# LPC11Axx register map
File version: 0.6
CPU: CM0 r0p0, little endian, no MPU, no FPU, 0x2 interrupt priority bits, 0x0 interrupts
Registers are 32-bit, read-write, reset 0x0 unless marked. A register's access mark holds for its fields unless they carry their own. Offsets are from the block's base; [hi:lo] are bit positions; 'fields as' and 'values as' point back to an identical list.

## IOCON — IOCON block
Base 0x40044000
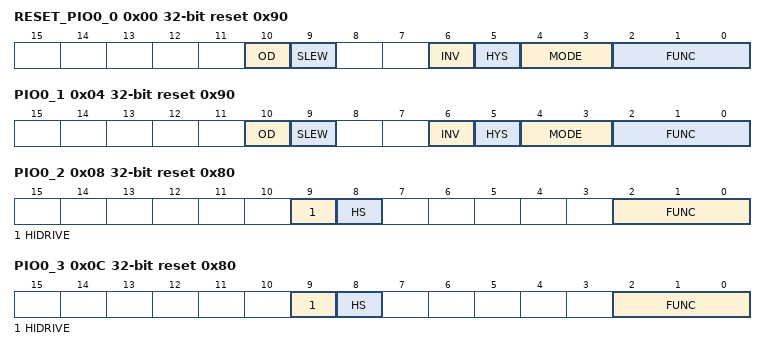
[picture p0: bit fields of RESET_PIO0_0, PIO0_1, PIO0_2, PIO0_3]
0x00 RESET_PIO0_0 reset 0x90 — I/O configuration register for pin RESET/PIO0_0
  [10] OD — Open-drain mode.
    0=DISABLE_; 1=OPEN_DRAIN_MODE_ENAB (Open-drain mode enabled. This is not a true open-drain mode. Input cannot be pulled up above VDD.)
  [9] SLEW — Driver slew rate
    0=SLOW (Slow. More outputs can be switched simultaneously.); 1=FAST
  [6] INV — Invert input
    0=INPUT_NOT_INVERTED_ (Input not inverted (HIGH on pin reads as 1, LOW on pin reads as 0).); 1=INPUT_INVERTED_HIGH (Input inverted (HIGH on pin reads as 0, LOW on pin reads as 1).)
  [5] HYS — Hysteresis.
    0=DISABLE_; 1=ENABLE_
  [4:3] MODE — Selects function mode (on-chip pull-up/pull-down resistor control).
    0=INACTIVE_NO_PULL_DO (Inactive (no pull-down/pull-up resistor enabled).); 1=PULL_DOWN_RESISTOR_E (Pull-down resistor enabled.); 2=PULL_UP_RESISTOR_ENA (Pull-up resistor enabled.); 3=REPEATER_MODE_
  [2:0] FUNC — Selects pin function for pin RESET/PIO0_0
    0=RESET (External reset input with fixed 20 ns glitch filter: A LOW on this pin resets the device, causing I/O ports and peripherals to take on their default states and processor execution to begin at address 0.); 1=PIO0_0 (General purpose digital input/output pin.)
0x04 PIO0_1 reset 0x90 — I/O configuration register for pin PIO0_1/RXD/CLKOUT/ CT32B0_MAT2/SSEL0/ CLKIN
  [10] OD — Open-drain mode.
    values as RESET_PIO0_0.OD
  [9] SLEW — Driver slew rate
    values as RESET_PIO0_0.SLEW
  [6] INV — Invert input
    values as RESET_PIO0_0.INV
  [5] HYS — Hysteresis.
    0=DISABLE_; 1=ENABLE_
  [4:3] MODE — Selects function mode (on-chip pull-up/pull-down resistor control).
    values as RESET_PIO0_0.MODE
  [2:0] FUNC — Selects pin function for pin PIO0_1/RXD/CLKOUT/ CT32B0_MAT2/SSEL0/ CLKIN
    0=PIO0_1 (General purpose digital input/output pin. A LOW level on this pin during reset starts the ISP command handler.); 1=RXD (Receiver data input for USART.); 2=CLKOUT (Clock output.); 3=CT32B0_MAT2 (Match output 2 for 32-bit timer 0.); 4=SSEL0 (Slave Select for SSP0.); 5=CLKIN (External clock input.)
0x08 PIO0_2 reset 0x80 — I/O configuration register for pin PIO0_2/SCL/ACMP_O/ TCK/SWCLK/ CT16B0_CAP0
  [9] HIDRIVE — Controls sink current.
    0=STANDARD (Standard; 4 mA sink current.); 1=HIGH (High; 20 mA sink current.)
  [8] HS — Controls glitch filter and slew rate.
    0=ENABLED; 1=DISABLED
  [2:0] FUNC — Selects pin function for pin PIO0_2/SCL/ACMP_O/ TCK/SWCLK/ CT16B0_CAP0
    0=PIO0_2 (General purpose digital input/output pin. High-current sink (20 mA) or standard-current sink (4 mA) programmable; true open-drain for all pin functions. Input glitch filter (50 ns) capable.); 1=SCL (I2C-bus clock (true open-drain) input/output. Input glitch filter (50 ns) capable.); 2=ACMP_O (Analog comparator output.); 3=TCK_SWCLK (Serial Wire Debug Clock (secondary for LQFP and HVQFN packages). Input glitch filter (50 ns) capable. For the WLCSP20 package only, this pin is configured to the SWCLK function by the boot loader after reset.); 4=CT16B0_CAP0 (Capture input 0 for 16-bit timer 0.Input glitch filter (50 ns) capable.)
0x0C PIO0_3 reset 0x80 — I/O configuration register for pin PIO0_3/SDA/ACMP_O/ SWDIO/CT16B1_CAP0
  [9] HIDRIVE — Controls sink current.
    values as PIO0_2.HIDRIVE
  [8] HS — Controls glitch filter and slew rate.
    0=ENABLED; 1=DISABLED
  [2:0] FUNC — Selects pin function for pin PIO0_3/SDA/ACMP_O/ SWDIO/CT16B1_CAP0
    0=PIO0_3 (General purpose digital input/output pin. High-current sink (20 mA) or standard-current sink (4 mA) programmable; true open-drain for all pin functions. Input glitch filter (50 ns) capable.); 1=SDA (I2C-bus data (true open-drain) input/output. Input glitch filter (50 ns) capable.); 2=ACMP_O (Analog comparator output.); 3=SWDIO (Serial Wire Debug I/O (secondary for LQFP and HVQFN packages). Input glitch filter (50 ns) capable. For the WLCSP20 package only, this pin is configured to the SWDIO function by the boot loader after reset.); 4=CT16B1_CAP0 (Capture input 0 for 16-bit timer 1. Input glitch filter (50 ns) capable.)
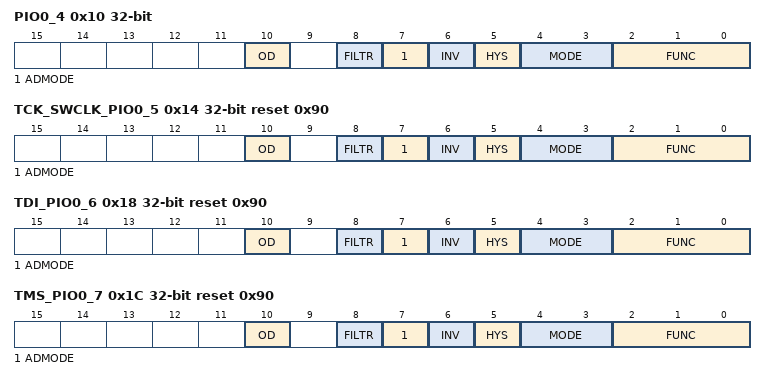
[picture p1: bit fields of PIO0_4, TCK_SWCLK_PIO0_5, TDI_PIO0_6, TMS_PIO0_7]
0x10 PIO0_4 reset not defined — I/O configuration register for pin PIO0_4/R/AOUT/ CT16B0_MAT1/MOSI0
  [10] OD — Open-drain mode.
    0=DISABLE_; 1=OPEN_DRAIN_MODE_ENAB (Open-drain mode enabled. This is not a true open-drain mode.)
  [8] FILTR — Selects 10 ns input glitch filter.
    0=FILTER_DISABLED_; 1=FILTER_ENABLED_
  [7] ADMODE — Selects Analog/Digital mode.
    0=ANALOG_INPUT_MODE_; 1=DIGITAL_FUNCTIONAL_M (Digital functional mode.)
  [6] INV — Invert input
    values as RESET_PIO0_0.INV
  [5] HYS — Hysteresis.
    0=DISABLE_; 1=ENABLE_
  [4:3] MODE — Selects function mode (on-chip pull-up/pull-down resistor control).
    values as RESET_PIO0_0.MODE
  [2:0] FUNC — Selects pin function for pin PIO0_4/R/AOUT/ CT16B0_MAT1/MOSI0
    0=PIO0_4 (General purpose digital input/output pin. Input glitch filter (10 ns) capable.); 1=R (Reserved.); 2=AOUT (D/A converter output.); 3=CT16B0_MAT1 (Match output 1 for 16-bit timer 0.); 4=MOSI0 (Master Out Slave In for SSP0. Input glitch filter (10 ns) capable.)
0x14 TCK_SWCLK_PIO0_5 reset 0x90 — I/O configuration register for pin TCK/SWCLK/PIO0_5/ R/CT16B0_MAT2/ SCK0
  [10] OD — Open-drain mode.
    values as PIO0_4.OD
  [8] FILTR — Selects 10 ns input glitch filter.
    0=FILTER_DISABLED_; 1=FILTER_ENABLED_
  [7] ADMODE — Selects Analog/Digital mode.
    values as PIO0_4.ADMODE
  [6] INV — Invert input
    values as RESET_PIO0_0.INV
  [5] HYS — Hysteresis.
    0=DISABLE_; 1=ENABLE_
  [4:3] MODE — Selects function mode (on-chip pull-up/pull-down resistor control).
    values as RESET_PIO0_0.MODE
  [2:0] FUNC — Selects pin function for pin TCK/SWCLK/PIO0_5/ R/CT16B0_MAT2/ SCK0
    0=TCK_SWCLK (Test clock TCK for JTAG interface and primary (default) Serial Wire Debug Clock. Input glitch filter (10 ns) capable.); 1=PIO0_5 (General purpose digital input/output pin. Input glitch filter (10 ns) capable.); 2=R (Reserved.); 3=CT16B0_MAT2 (Match output 2 for 16-bit timer 0.); 4=SCK0 (Serial clock for SSP0. Input glitch filter (10 ns) capable.)
0x18 TDI_PIO0_6 reset 0x90 — I/O configuration register for pin TDI/PIO0_6/AD0/ CT32B0_MAT3/MISO0
  [10] OD — Open-drain mode.
    values as PIO0_4.OD
  [8] FILTR — Selects 10 ns input glitch filter.
    0=FILTER_DISABLED_; 1=FILTER_ENABLED_
  [7] ADMODE — Selects Analog/Digital mode.
    values as PIO0_4.ADMODE
  [6] INV — Invert input
    values as RESET_PIO0_0.INV
  [5] HYS — Hysteresis.
    0=DISABLE_; 1=ENABLE_
  [4:3] MODE — Selects function mode (on-chip pull-up/pull-down resistor control).
    values as RESET_PIO0_0.MODE
  [2:0] FUNC — Selects pin function for pin TDI/PIO0_6/AD0/ CT32B0_MAT3/MISO0
    0=TDI (Test Data In for JTAG interface. Input glitch filter (10 ns) capable.); 1=PIO0_6 (General purpose digital input/output pin. Input glitch filter (10 ns) capable.); 2=AD0 (A/D converter input 0.); 3=CT32B0_MAT3 (Match output 3 for 32-bit timer 0.); 4=MISO0 (Master In Slave Out for SSP0. Input glitch filter (10 ns) capable.)
0x1C TMS_PIO0_7 reset 0x90 — I/O configuration register for pin TMS/PIO0_7/AD1/ CT32B1_CAP0/ CT16B0_MAT0
  [10] OD — Open-drain mode.
    values as PIO0_4.OD
  [8] FILTR — Selects 10 ns input glitch filter.
    0=FILTER_DISABLED_; 1=FILTER_ENABLED_
  [7] ADMODE — Selects Analog/Digital mode.
    values as PIO0_4.ADMODE
  [6] INV — Invert input
    values as RESET_PIO0_0.INV
  [5] HYS — Hysteresis.
    0=DISABLE_; 1=ENABLE_
  [4:3] MODE — Selects function mode (on-chip pull-up/pull-down resistor control).
    values as RESET_PIO0_0.MODE
  [2:0] FUNC — Selects pin function for pin TMS/PIO0_7/AD1/ CT32B1_CAP0/ CT16B0_MAT0
    0=TMS (Test Mode Select for JTAG interface. Input glitch filter (10 ns) capable.); 1=PIO0_7 (General purpose digital input/output pin. Input glitch filter (10 ns) capable.); 2=AD1 (A/D converter input 1.); 3=CT32B1_CAP0 (Capture input 0 for 32-bit timer 1. Input glitch filter (10 ns) capable.); 4=CT16B0_MAT0 (Match output 2 for 16-bit timer 0.)
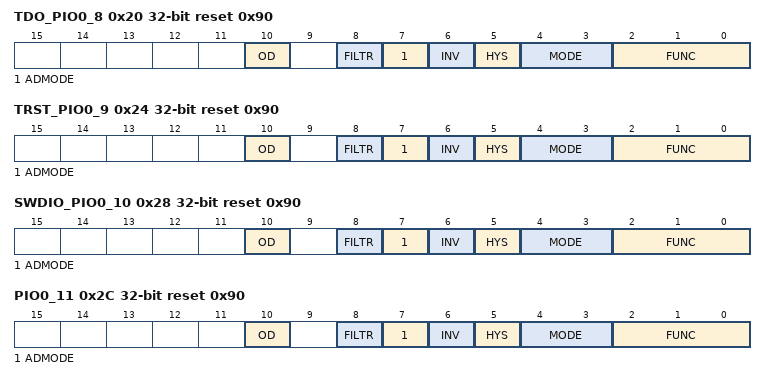
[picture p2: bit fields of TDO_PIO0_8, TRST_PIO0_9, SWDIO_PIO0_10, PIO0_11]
0x20 TDO_PIO0_8 reset 0x90 — I/O configuration register for pin TDO/PIO0_8/AD2/ CT32B1_MAT0/SCK1
  [10] OD — Open-drain mode.
    values as PIO0_4.OD
  [8] FILTR — Selects 10 ns input glitch filter.
    0=FILTER_DISABLED_; 1=FILTER_ENABLED_
  [7] ADMODE — Selects Analog/Digital mode.
    values as PIO0_4.ADMODE
  [6] INV — Invert input
    values as RESET_PIO0_0.INV
  [5] HYS — Hysteresis.
    0=DISABLE_; 1=ENABLE_
  [4:3] MODE — Selects function mode (on-chip pull-up/pull-down resistor control).
    values as RESET_PIO0_0.MODE
  [2:0] FUNC — Selects pin function for pin TDO/PIO0_8/AD2/ CT32B1_MAT0/SCK1
    0=TDO (Test Data Out for JTAG interface.); 1=PIO0_8 (General purpose digital input/output pin. Input glitch filter (10 ns) capable.); 2=AD2 (A/D converter input 2.); 3=CT32B1_MAT0 (Match output 0 for 32-bit timer 1.); 4=SCK1 (Serial clock for SSP1. Input glitch filter (10 ns) capable.)
0x24 TRST_PIO0_9 reset 0x90 — I/O configuration register for pin TRST/PIO0_9/AD3/CT32B1_MAT1/CT16B0_MAT1/CTS
  [10] OD — Open-drain mode.
    values as PIO0_4.OD
  [8] FILTR — Selects 10 ns input glitch filter.
    0=FILTER_DISABLED_; 1=FILTER_ENABLED_
  [7] ADMODE — Selects Analog/Digital mode.
    values as PIO0_4.ADMODE
  [6] INV — Invert input
    values as RESET_PIO0_0.INV
  [5] HYS — Hysteresis.
    0=DISABLE_; 1=ENABLE_
  [4:3] MODE — Selects function mode (on-chip pull-up/pull-down resistor control).
    values as RESET_PIO0_0.MODE
  [2:0] FUNC — Selects pin function for pin TRST/PIO0_9/AD3/CT32B1_MAT1/CT16B0_MAT1/CTS
    0=TRST (Test Reset for JTAG interface. Input glitch filter (10 ns) capable.); 1=PIO0_9 (General purpose digital input/output pin. Input glitch filter (10 ns) capable.); 2=AD3 (A/D converter, input 3.); 3=CT32B1_MAT1 (Match output 1 for 32-bit timer 1.); 4=CT16B0_MAT1 (Match output 1 for 16-bit timer 0.); 5=CTS (Clear To Send input for USART. Input glitch filter (10 ns) capable.)
0x28 SWDIO_PIO0_10 reset 0x90 — I/O configuration register for pin SWDIO/PIO0_10/AD4/ CT32B1_MAT2/ CT16B0_MAT2/RTS
  [10] OD — Open-drain mode.
    values as PIO0_4.OD
  [8] FILTR — Selects 10 ns input glitch filter.
    0=FILTER_DISABLED_; 1=FILTER_ENABLED_
  [7] ADMODE — Selects Analog/Digital mode.
    values as PIO0_4.ADMODE
  [6] INV — Invert input
    values as RESET_PIO0_0.INV
  [5] HYS — Hysteresis.
    0=DISABLE_; 1=ENABLE_
  [4:3] MODE — Selects function mode (on-chip pull-up/pull-down resistor control).
    values as RESET_PIO0_0.MODE
  [2:0] FUNC — Selects pin function for pin SWDIO/PIO0_10/AD4/ CT32B1_MAT2/ CT16B0_MAT2/RTS
    0=SWDIO (Primary (default) Serial Wire Debug I/O for the LQFP48 and HVQFN33 packages. For the WLCSP20 package, use PIO0_3. Input glitch filter (10 ns) capable.); 1=PIO0_10 (General purpose digital input/output pin. Input glitch filter (10 ns) capable.); 2=AD4 (A/D converter, input 4.); 3=CT32B1_MAT2 (Match output 2 for 32-bit timer 1.); 4=CT16B0_MAT2 (Match output 2 for 16-bit timer 0.); 5=RTS (Request To Send output for USART.)
0x2C PIO0_11 reset 0x90 — I/O configuration register for pin PIO0_11/SCLK/ AD5/CT32B1_MAT3/ CT32B0_CAP0
  [10] OD — Open-drain mode.
    values as PIO0_4.OD
  [8] FILTR — Selects 10 ns input glitch filter.
    0=FILTER_DISABLED_; 1=FILTER_ENABLED_
  [7] ADMODE — Selects Analog/Digital mode.
    values as PIO0_4.ADMODE
  [6] INV — Invert input
    values as RESET_PIO0_0.INV
  [5] HYS — Hysteresis.
    0=DISABLE_; 1=ENABLE_
  [4:3] MODE — Selects function mode (on-chip pull-up/pull-down resistor control).
    values as RESET_PIO0_0.MODE
  [2:0] FUNC — Selects pin function for pin PIO0_11/SCLK/ AD5/CT32B1_MAT3/ CT32B0_CAP0
    0=PIO0_11 (General purpose digital input/output pin. Input glitch filter (10 ns) capable.); 1=SCLK (Serial clock for USART. Input glitch filter (10 ns) capable.); 2=AD5 (A/D converter, input 5.); 3=CT32B1_MAT3 (Match output 3 for 32-bit timer 1.); 4=CT32B0_CAP0 (Capture input 0 for 32-bit timer 0. Input glitch filter (10 ns) capable.)
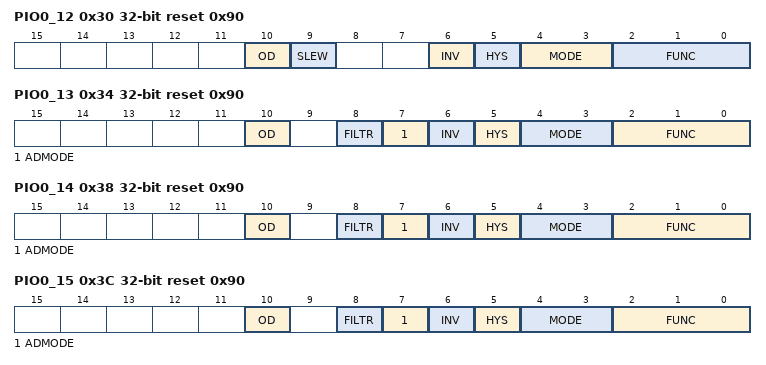
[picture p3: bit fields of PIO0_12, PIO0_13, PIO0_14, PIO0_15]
0x30 PIO0_12 reset 0x90 — I/O configuration register for pin PIO0_12/RXD/ ACMP_O/ CT32B0_MAT0/SCL/ CLKIN
  [10] OD — Open-drain mode.
    values as RESET_PIO0_0.OD
  [9] SLEW — Driver slew rate
    values as RESET_PIO0_0.SLEW
  [6] INV — Invert input
    values as RESET_PIO0_0.INV
  [5] HYS — Hysteresis.
    0=DISABLE_; 1=ENABLE_
  [4:3] MODE — Selects function mode (on-chip pull-up/pull-down resistor control).
    values as RESET_PIO0_0.MODE
  [2:0] FUNC — Selects pin function for pin PIO0_12/RXD/ ACMP_O/ CT32B0_MAT0/SCL/ CLKIN
    0=PIO0_12 (General purpose digital input/output pin.); 1=RXD (Receiver data input for USART. This pin is used for ISP communication.); 2=ACMP_O (Analog comparator output.); 3=CT32B0_MAT0 (Match output 0 for 32-bit timer 0.); 4=SCL (I2C-bus clock input/output. This is not an I2C-bus open-drain pin[8].); 5=CLKIN (External clock input.)
0x34 PIO0_13 reset 0x90 — I/O configuration register for pin PIO0_13/TXD/ ACMP_I2/ CT32B0_MAT1/SDA
  [10] OD — Open-drain mode.
    values as PIO0_4.OD
  [8] FILTR — Selects 10 ns input glitch filter.
    0=FILTER_DISABLED_; 1=FILTER_ENABLED_
  [7] ADMODE — Selects Analog/Digital mode.
    values as PIO0_4.ADMODE
  [6] INV — Invert input
    values as RESET_PIO0_0.INV
  [5] HYS — Hysteresis.
    0=DISABLE_; 1=ENABLE_
  [4:3] MODE — Selects function mode (on-chip pull-up/pull-down resistor control).
    values as RESET_PIO0_0.MODE
  [2:0] FUNC — Selects pin function for pin PIO0_13/TXD/ ACMP_I2/ CT32B0_MAT1/SDA
    0=PIO0_13 (General purpose digital input/output pin. Input glitch filter (10 ns) capable.); 1=TXD (Transmitter data output for USART. This pin is used for ISP communication.); 2=ACMP_I2 (Analog comparator input 2.); 3=CT32B0_MAT1 (Match output 1 for 32-bit timer 0.); 4=SDA (I2C-bus data input/output. This is not an I2C-bus open-drain pin[8]. Input glitch filter (10 ns) capable.)
0x38 PIO0_14 reset 0x90 — I/O configuration register for pin PIO0_14/MISO1/AD6/CT32B0_CAP1/CT16B1_MAT1/VDDCMP
  [10] OD — Open-drain mode.
    values as PIO0_4.OD
  [8] FILTR — Selects 10 ns input glitch filter.
    0=FILTER_DISABLED_; 1=FILTER_ENABLED_
  [7] ADMODE — Selects Analog/Digital mode.
    values as PIO0_4.ADMODE
  [6] INV — Invert input
    values as RESET_PIO0_0.INV
  [5] HYS — Hysteresis.
    0=DISABLE_; 1=ENABLE_
  [4:3] MODE — Selects function mode (on-chip pull-up/pull-down resistor control).
    values as RESET_PIO0_0.MODE
  [2:0] FUNC — Selects pin function for pin PIO0_14/MISO1/AD6/CT32B0_CAP1/CT16B1_MAT1/xxxCMP
    0=PIO0_14 (General purpose digital input/output pin. Input glitch filter (10 ns) capable.); 1=MISO1 (Master In Slave Out for SSP1. Input glitch filter (10 ns) capable.); 2=AD6 (A/D converter, input 6.); 3=CT32B0_CAP1 (Capture input 1 for 32-bit timer 0. Input glitch filter (10 ns) capable.); 4=CT16B1_MAT1 (Match output 1 for 16-bit timer 1.); 5=VDDCMP (Analog comparator alternate reference voltage.)
0x3C PIO0_15 reset 0x90 — I/O configuration register for pin PIO0_15/TXD/AD7/ CT32B0_CAP2/SDA
  [10] OD — Open-drain mode.
    values as PIO0_4.OD
  [8] FILTR — Selects 10 ns input glitch filter.
    0=FILTER_DISABLED_; 1=FILTER_ENABLED_
  [7] ADMODE — Selects Analog/Digital mode.
    values as PIO0_4.ADMODE
  [6] INV — Invert input
    values as RESET_PIO0_0.INV
  [5] HYS — Hysteresis.
    0=DISABLE_; 1=ENABLE_
  [4:3] MODE — Selects function mode (on-chip pull-up/pull-down resistor control).
    values as RESET_PIO0_0.MODE
  [2:0] FUNC — Selects pin function for pin PIO0_15/TXD/AD7/ CT32B0_CAP2/SDA
    0=PIO0_15 (General purpose digital input/output pin. Input glitch filter (10 ns) capable.); 1=TXD (Transmitter data output for USART.); 2=AD7 (A/D converter, input 7.); 3=CT32B0_CAP2 (Capture input 2 for 32-bit timer 0. Input glitch filter (10 ns) capable.); 4=SDA (I2C-bus data input/output. This is not an I2C-bus open-drain pin[8]. Input glitch filter (10 ns) capable.)
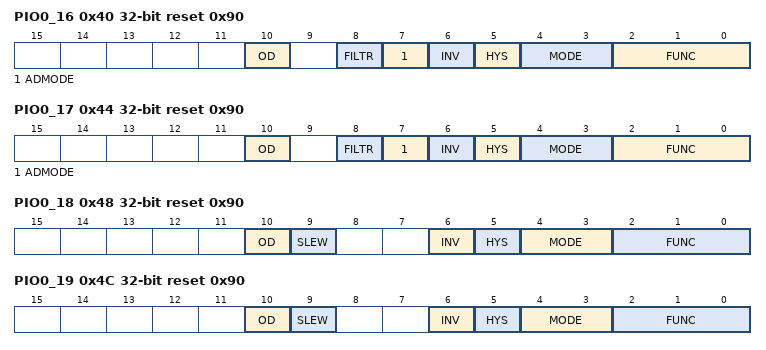
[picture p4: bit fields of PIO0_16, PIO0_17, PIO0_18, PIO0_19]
0x40 PIO0_16 reset 0x90 — I/O configuration register for pin PIO0_16/ ATRG0/ACMP_I3/ CT16B0_CAP1/SCL
  [10] OD — Open-drain mode.
    values as PIO0_4.OD
  [8] FILTR — Selects 10 ns input glitch filter.
    0=FILTER_DISABLED_; 1=FILTER_ENABLED_
  [7] ADMODE — Selects Analog/Digital mode.
    values as PIO0_4.ADMODE
  [6] INV — Invert input
    values as RESET_PIO0_0.INV
  [5] HYS — Hysteresis.
    0=DISABLE_; 1=ENABLE_
  [4:3] MODE — Selects function mode (on-chip pull-up/pull-down resistor control).
    values as RESET_PIO0_0.MODE
  [2:0] FUNC — Selects pin function for pin PIO0_16/ ATRG0/ACMP_I3/ CT16B0_CAP1/SCL
    0=PIO0_16 (General purpose digital input/output pin. Input glitch filter (10 ns) capable.); 1=ATRG0 (Conversion trigger 0 for ADC or DAC. Input glitch filter (10 ns) capable.); 2=ACMP_I3 (Analog comparator input 3.); 3=CT16B0_CAP1 (Capture input 1 for 16-bit timer 0. Input glitch filter (10 ns) capable.); 4=SCL (I2C-bus clock input/output. This is not an I2C-bus open-drain pin[8]. Input glitch filter (10 ns) capable.)
0x44 PIO0_17 reset 0x90 — I/O configuration register for pin PIO0_17/ ATRG1/ACMP_I4/ CT16B0_CAP2/ CT16B0_MAT0
  [10] OD — Open-drain mode.
    values as PIO0_4.OD
  [8] FILTR — Selects 10 ns input glitch filter.
    0=FILTER_DISABLED_; 1=FILTER_ENABLED_
  [7] ADMODE — Selects Analog/Digital mode.
    values as PIO0_4.ADMODE
  [6] INV — Invert input
    values as RESET_PIO0_0.INV
  [5] HYS — Hysteresis.
    0=DISABLE_; 1=ENABLE_
  [4:3] MODE — Selects function mode (on-chip pull-up/pull-down resistor control).
    values as RESET_PIO0_0.MODE
  [2:0] FUNC — Selects pin function for pin PIO0_17/ ATRG1/ACMP_I4/ CT16B0_CAP2/ CT16B0_MAT0
    0=PIO0_17 (General purpose digital input/output pin. Input glitch filter (10 ns) capable.); 1=ATRG1 (Conversion trigger 1 for ADC or DAC. Input glitch filter (10 ns) capable.); 2=ACMP_I4 (Analog comparator input 4.); 3=CT16B0_CAP2 (Capture input 2 for 16-bit timer 0. Input glitch filter (10 ns) capable.); 4=CT16B0_MAT0 (Match output 0 for 16-bit timer 0.)
0x48 PIO0_18 reset 0x90 — I/O configuration register for pin PIO0_18/R/SSEL0/ CT16B0_CAP0/ CT16B1_CAP1
  [10] OD — Open-drain mode.
    values as RESET_PIO0_0.OD
  [9] SLEW — Driver slew rate
    values as RESET_PIO0_0.SLEW
  [6] INV — Invert input
    values as RESET_PIO0_0.INV
  [5] HYS — Hysteresis.
    0=DISABLE_; 1=ENABLE_
  [4:3] MODE — Selects function mode (on-chip pull-up/pull-down resistor control).
    values as RESET_PIO0_0.MODE
  [2:0] FUNC — Selects pin function for pin PIO0_18/R/SSEL0/ CT16B0_CAP0/ CT16B1_CAP1
    0=PIO0_18 (General purpose digital input/output pin.); 1=R (Reserved.); 2=SSEL0 (Slave Select for SSP0.); 3=CT16B0_CAP0 (Capture input 0 for 16-bit timer 0.); 4=CT16B1_CAP1 (Capture input 1 for 16-bit timer 1.)
0x4C PIO0_19 reset 0x90 — I/O configuration register for pin PIO0_19/CLKIN/ CLKOUT/ MOSI0/CT16B1_MAT0
  [10] OD — Open-drain mode.
    values as RESET_PIO0_0.OD
  [9] SLEW — Driver slew rate
    values as RESET_PIO0_0.SLEW
  [6] INV — Invert input
    values as RESET_PIO0_0.INV
  [5] HYS — Hysteresis.
    0=DISABLE_; 1=ENABLE_
  [4:3] MODE — Selects function mode (on-chip pull-up/pull-down resistor control).
    values as RESET_PIO0_0.MODE
  [2:0] FUNC — Selects pin function for pin PIO0_19/CLKIN/ CLKOUT/ MOSI0/CT16B1_MAT0
    0=PIO0_19 (General purpose digital input/output pin.); 1=CLKIN (External clock input.); 2=CLKOUT (Clock output.); 3=MOSI0 (Master Out Slave In for SSP0.); 4=CT16B1_MAT0 (Match output 0 for 16-bit timer 1.)
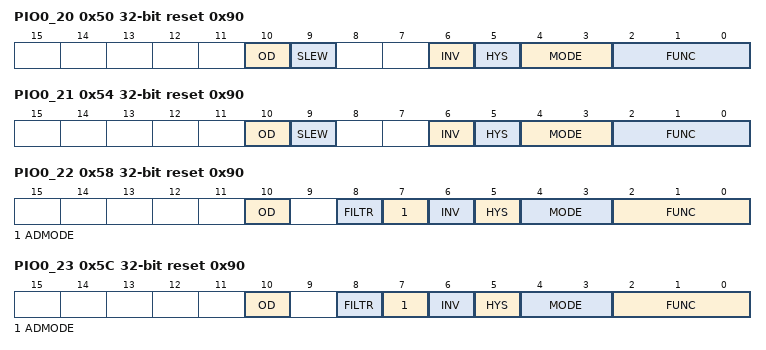
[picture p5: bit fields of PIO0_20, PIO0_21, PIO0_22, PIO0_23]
0x50 PIO0_20 reset 0x90 — I/O configuration register for pin PIO0_20/R/SCK0/ CT32B1_CAP0/ CT16B1_MAT2
  [10] OD — Open-drain mode.
    values as RESET_PIO0_0.OD
  [9] SLEW — Driver slew rate
    values as RESET_PIO0_0.SLEW
  [6] INV — Invert input
    values as RESET_PIO0_0.INV
  [5] HYS — Hysteresis.
    0=DISABLE_; 1=ENABLE_
  [4:3] MODE — Selects function mode (on-chip pull-up/pull-down resistor control).
    values as RESET_PIO0_0.MODE
  [2:0] FUNC — Selects pin function for pin PIO0_20/R/SCK0/ CT32B1_CAP0/ CT16B1_MAT2
    0=PIO0_20 (General purpose digital input/output pin.); 1=R (Reserved.); 2=SCK0 (Serial clock for SSP0.); 3=CT32B1_CAP0 (Capture input 0 for 32-bit timer 1.); 4=CT16B1_MAT2 (Match output 2 for 16-bit timer 1.)
0x54 PIO0_21 reset 0x90 — I/O configuration register for pin PIO0_21/CTS/ ACMP_O/ CT32B1_CAP1/SCLK
  [10] OD — Open-drain mode.
    values as RESET_PIO0_0.OD
  [9] SLEW — Driver slew rate
    values as RESET_PIO0_0.SLEW
  [6] INV — Invert input
    values as RESET_PIO0_0.INV
  [5] HYS — Hysteresis.
    0=DISABLE_; 1=ENABLE_
  [4:3] MODE — Selects function mode (on-chip pull-up/pull-down resistor control).
    values as RESET_PIO0_0.MODE
  [2:0] FUNC — Selects pin function for pin PIO0_21/CTS/ ACMP_O/ CT32B1_CAP1/SCLK
    0=PIO0_21 (General purpose digital input/output pin. If configured as output, this pin is a high-current source output driver (20 mA).); 1=CTS (Clear To Send input for USART.); 2=ACMP_O (Analog comparator output.); 3=CT32B1_CAP1 (Capture input 1 for 32-bit timer 1.); 4=SCLK (Serial clock for USART.)
0x58 PIO0_22 reset 0x90 — I/O configuration register for pin PIO0_22/MISO0/ ACMP_I5/ CT32B1_MAT2/ CT32B1_CAP2
  [10] OD — Open-drain mode.
    values as PIO0_4.OD
  [8] FILTR — Selects 10 ns input glitch filter.
    0=FILTER_DISABLED_; 1=FILTER_ENABLED_
  [7] ADMODE — Selects Analog/Digital mode.
    values as PIO0_4.ADMODE
  [6] INV — Invert input
    values as RESET_PIO0_0.INV
  [5] HYS — Hysteresis.
    0=DISABLE_; 1=ENABLE_
  [4:3] MODE — Selects function mode (on-chip pull-up/pull-down resistor control).
    values as RESET_PIO0_0.MODE
  [2:0] FUNC — Selects pin function for pin PIO0_22/MISO0/ ACMP_I5/ CT32B1_MAT2/ CT32B1_CAP2
    0=PIO0_22 (General purpose digital input/output pin. Input glitch filter (10 ns) capable.); 1=MISO0 (Master In Slave Out for SSP0. Input glitch filter (10 ns) capable.); 2=ACMP_I5 (Analog comparator input 5.); 3=CT32B1_MAT2 (Match output 2 for 32-bit timer 1.); 4=CT32B1_CAP2 (Capture input 2 for 32-bit timer 1. Input glitch filter (10 ns) capable.)
0x5C PIO0_23 reset 0x90 — I/O configuration register for pin PIO0_23/RTS/ ACMP_O/ CT32B0_CAP0/SCLK
  [10] OD — Open-drain mode.
    values as PIO0_4.OD
  [8] FILTR — Selects 10 ns input glitch filter.
    0=FILTER_DISABLED_; 1=FILTER_ENABLED_
  [7] ADMODE — Selects Analog/Digital mode.
    values as PIO0_4.ADMODE
  [6] INV — Invert input
    values as RESET_PIO0_0.INV
  [5] HYS — Hysteresis.
    0=DISABLE_; 1=ENABLE_
  [4:3] MODE — Selects function mode (on-chip pull-up/pull-down resistor control).
    values as RESET_PIO0_0.MODE
  [2:0] FUNC — Selects pin function for pin PIO0_23/RTS/ ACMP_O/ CT32B0_CAP0/SCLK
    0=PIO0_23 (General purpose digital input/output pin.); 1=RTS (Request To Send output for USART.); 2=ACMP_O (Analog comparator output.); 3=CT32B0_CAP0 (Capture input 0 for 32-bit timer 0.); 4=SCLK (Serial clock for USART.)
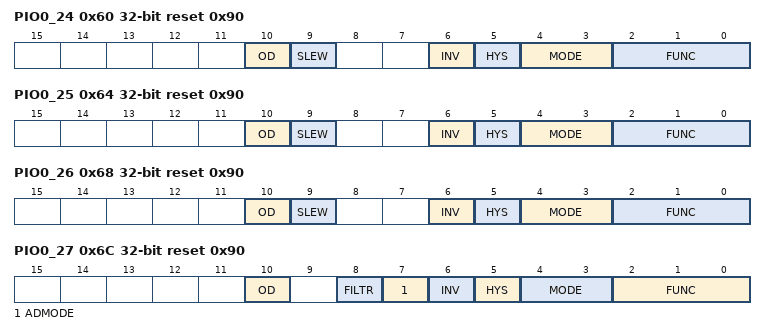
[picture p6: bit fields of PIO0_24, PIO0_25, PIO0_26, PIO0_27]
0x60 PIO0_24 reset 0x90 — I/O configuration register for pin PIO0_24/SCL/CLKIN/ CT16B1_CAP0
  [10] OD — Open-drain mode.
    values as RESET_PIO0_0.OD
  [9] SLEW — Driver slew rate
    values as RESET_PIO0_0.SLEW
  [6] INV — Invert input
    values as RESET_PIO0_0.INV
  [5] HYS — Hysteresis.
    0=DISABLE_; 1=ENABLE_
  [4:3] MODE — Selects function mode (on-chip pull-up/pull-down resistor control).
    values as RESET_PIO0_0.MODE
  [2:0] FUNC — Selects pin function for pin PIO0_24/SCL/CLKIN/ CT16B1_CAP0
    0=PIO0_24 (General purpose digital input/output pin.); 1=SCL (I2C-bus clock input/output. This is not an I2C-bus open-drain pin[8].); 2=CLKIN (External clock input.); 3=CT16B1_CAP0 (Capture input 0 for 16-bit timer 1.)
0x64 PIO0_25 reset 0x90 — I/O configuration register for pin PIO0_25/SDA/SSEL1/ CT16B1_MAT0
  [10] OD — Open-drain mode.
    values as RESET_PIO0_0.OD
  [9] SLEW — Driver slew rate
    values as RESET_PIO0_0.SLEW
  [6] INV — Invert input
    values as RESET_PIO0_0.INV
  [5] HYS — Hysteresis.
    0=DISABLE_; 1=ENABLE_
  [4:3] MODE — Selects function mode (on-chip pull-up/pull-down resistor control).
    values as RESET_PIO0_0.MODE
  [2:0] FUNC — Selects pin function for pin PIO0_25/SDA/SSEL1/ CT16B1_MAT0
    0=PIO0_25 (General purpose digital input/output pin.); 1=SDA (I2C-bus data input/output. This is not an I2C-bus open-drain pin[8].); 2=SSEL1 (Slave Select for SSP1.); 3=CT16B1_MAT0 (Match output 0 for 16-bit timer 1.)
0x68 PIO0_26 reset 0x90 — I/O configuration register for pin PIO0_26/TXD/MISO1/ CT16B1_CAP1/ CT32B0_CAP2
  [10] OD — Open-drain mode.
    values as RESET_PIO0_0.OD
  [9] SLEW — Driver slew rate
    values as RESET_PIO0_0.SLEW
  [6] INV — Invert input
    values as RESET_PIO0_0.INV
  [5] HYS — Hysteresis.
    0=DISABLE_; 1=ENABLE_
  [4:3] MODE — Selects function mode (on-chip pull-up/pull-down resistor control).
    values as RESET_PIO0_0.MODE
  [2:0] FUNC — Selects pin function for pin PIO0_26/TXD/MISO1/ CT16B1_CAP1/ CT32B0_CAP2
    0=PIO0_26 (General purpose digital input/output pin.); 1=TXD (Transmitter data output for USART.); 2=MISO1 (Master In Slave Out for SSP1.); 3=CT16B1_CAP1 (Capture input 1 for 16-bit timer 1.); 4=CT32B0_CAP2 (Capture input 2 for 32-bit timer 0.)
0x6C PIO0_27 reset 0x90 — I/O configuration register for pin PIO0_27/MOSI1/ ACMP_I1/ CT32B1_MAT1/ CT16B1_CAP2
  [10] OD — Open-drain mode.
    values as PIO0_4.OD
  [8] FILTR — Selects 10 ns input glitch filter.
    0=FILTER_DISABLED_; 1=FILTER_ENABLED_
  [7] ADMODE — Selects Analog/Digital mode.
    values as PIO0_4.ADMODE
  [6] INV — Invert input
    values as RESET_PIO0_0.INV
  [5] HYS — Hysteresis.
    0=DISABLE_; 1=ENABLE_
  [4:3] MODE — Selects function mode (on-chip pull-up/pull-down resistor control).
    values as RESET_PIO0_0.MODE
  [2:0] FUNC — Selects pin function for pin PIO0_27/MOSI1/ ACMP_I1/ CT32B1_MAT1/ CT16B1_CAP2
    0=PIO0_27 (General purpose digital input/output pin. Input glitch filter (10 ns) capable.); 1=MOSI1 (Master Out Slave In for SSP1. Input glitch filter (10 ns) capable.); 2=ACMP_I1 (Analog comparator input 1.); 3=CT32B1_MAT1 (Match output 1 for 32-bit timer 1.); 4=CT16B1_CAP2 (Capture input 2 for 16-bit timer 1. Input glitch filter (10 ns) capable.)
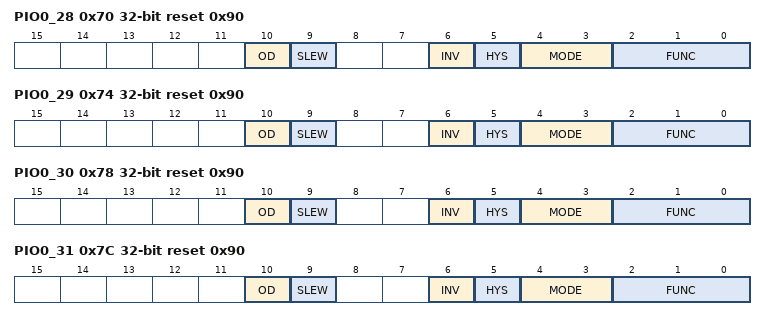
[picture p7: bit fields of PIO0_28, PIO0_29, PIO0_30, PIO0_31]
0x70 PIO0_28 reset 0x90 — I/O configuration register for pin PIO0_28/DTR/SSEL1/ CT32B0_CAP0
  [10] OD — Open-drain mode.
    values as RESET_PIO0_0.OD
  [9] SLEW — Driver slew rate
    values as RESET_PIO0_0.SLEW
  [6] INV — Invert input
    values as RESET_PIO0_0.INV
  [5] HYS — Hysteresis.
    0=DISABLE_; 1=ENABLE_
  [4:3] MODE — Selects function mode (on-chip pull-up/pull-down resistor control).
    values as RESET_PIO0_0.MODE
  [2:0] FUNC — Selects pin function for pin PIO0_28/DTR/SSEL1/ CT32B0_CAP0
    0=PIO0_28 (General purpose digital input/output pin.); 1=DTR (Data Terminal Ready output for USART.); 2=SSEL1 (Slave Select for SSP1.); 3=CT32B0_CAP0 (Capture input 0 for 32-bit timer 0.)
0x74 PIO0_29 reset 0x90 — I/O configuration register for pin PIO0_29/DSR/SCK1/ CT32B0_CAP1
  [10] OD — Open-drain mode.
    values as RESET_PIO0_0.OD
  [9] SLEW — Driver slew rate
    values as RESET_PIO0_0.SLEW
  [6] INV — Invert input
    values as RESET_PIO0_0.INV
  [5] HYS — Hysteresis.
    0=DISABLE_; 1=ENABLE_
  [4:3] MODE — Selects function mode (on-chip pull-up/pull-down resistor control).
    values as RESET_PIO0_0.MODE
  [2:0] FUNC — Selects pin function for pin PIO0_29/DSR/SCK1/ CT32B0_CAP1
    0=PIO0_29 (General purpose digital input/output pin.); 1=DSR (Data Set Ready input for USART.); 2=SCK1 (Serial clock for SSP1.); 3=CT32B0_CAP1 (Capture input 1 for 32-bit timer 0.)
0x78 PIO0_30 reset 0x90 — I/O configuration register for pin PIO0_30/RI/MOSI1/ CT32B0_MAT0/ CT16B0_CAP0
  [10] OD — Open-drain mode.
    values as RESET_PIO0_0.OD
  [9] SLEW — Driver slew rate
    values as RESET_PIO0_0.SLEW
  [6] INV — Invert input
    values as RESET_PIO0_0.INV
  [5] HYS — Hysteresis.
    0=DISABLE_; 1=ENABLE_
  [4:3] MODE — Selects function mode (on-chip pull-up/pull-down resistor control).
    values as RESET_PIO0_0.MODE
  [2:0] FUNC — Selects pin function for pin PIO0_30/RI/MOSI1/ CT32B0_MAT0/ CT16B0_CAP0
    0=PIO0_30 (General purpose digital input/output pin.); 1=RI (Ring Indicator input for USART.); 2=MOSI1 (Master Out Slave In for SSP1.); 3=CT32B0_MAT0 (Match output 0 for 32-bit timer 0.); 4=CT16B0_CAP0 (Capture input 0 for 16-bit timer 0.)
0x7C PIO0_31 reset 0x90 — I/O configuration register for pin PIO0_31/RI/MOSI1/ CT32B1_MAT0/ CT16B1_CAP1
  [10] OD — Open-drain mode.
    values as RESET_PIO0_0.OD
  [9] SLEW — Driver slew rate
    values as RESET_PIO0_0.SLEW
  [6] INV — Invert input
    values as RESET_PIO0_0.INV
  [5] HYS — Hysteresis.
    0=DISABLE_; 1=ENABLE_
  [4:3] MODE — Selects function mode (on-chip pull-up/pull-down resistor control).
    values as RESET_PIO0_0.MODE
  [2:0] FUNC — Selects pin function for pin PIO0_31/RI/MOSI1/ CT32B1_MAT0/ CT16B1_CAP1
    0=PIO0_31 (General purpose digital input/output pin.); 1=RI (Ring Indicator input for USART.); 2=MOSI1 (Master Out Slave In for SSP1.); 3=CT32B1_MAT0 (Match output 0 for 32-bit timer 1.); 4=CT16B1_CAP1 (Capture input 1 for 16-bit timer 1.)
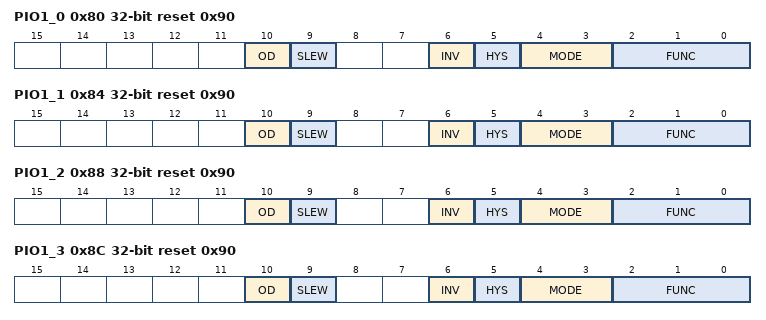
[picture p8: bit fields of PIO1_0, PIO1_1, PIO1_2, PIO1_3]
0x80 PIO1_0 reset 0x90 — I/O configuration register for pin PIO1_0/DCD/SCK0/ CT32B1_MAT3/ CT16B0_MAT1
  [10] OD — Open-drain mode.
    values as RESET_PIO0_0.OD
  [9] SLEW — Driver slew rate
    values as RESET_PIO0_0.SLEW
  [6] INV — Invert input
    values as RESET_PIO0_0.INV
  [5] HYS — Hysteresis.
    0=DISABLE_; 1=ENABLE_
  [4:3] MODE — Selects function mode (on-chip pull-up/pull-down resistor control).
    values as RESET_PIO0_0.MODE
  [2:0] FUNC — Selects pin function for pin PIO1_0/DCD/SCK0/ CT32B1_MAT3/ CT16B0_MAT1
    0=PIO1_0 (General purpose digital input/output pin.); 1=DCD (Data Carrier Detect input for USART.); 2=SCK0 (Serial clock for SSP0.); 3=CT32B1_MAT3 (Match output 3 for 32-bit timer 1.); 4=CT16B0_MAT1 (Match output 1 for 16-bit timer 0.)
0x84 PIO1_1 reset 0x90 — I/O configuration register for pin PIO1_1/DTR/SSEL0/ CT32B1_MAT3/ CT16B1_MAT0
  [10] OD — Open-drain mode.
    values as RESET_PIO0_0.OD
  [9] SLEW — Driver slew rate
    values as RESET_PIO0_0.SLEW
  [6] INV — Invert input
    values as RESET_PIO0_0.INV
  [5] HYS — Hysteresis.
    0=DISABLE_; 1=ENABLE_
  [4:3] MODE — Selects function mode (on-chip pull-up/pull-down resistor control).
    values as RESET_PIO0_0.MODE
  [2:0] FUNC — Selects pin function for pin PIO1_1/DTR/SSEL0/ CT32B1_MAT3/ CT16B1_MAT0
    0=PIO1_1 (General purpose digital input/output pin.); 1=DTR (Data Terminal Ready output for USART.); 2=SSEL0 (Slave Select for SSP0.); 3=CT32B1_MAT3 (Match output 3 for 32-bit timer 1.); 4=CT16B1_MAT0 (Match output 0 for 16-bit timer 1.)
0x88 PIO1_2 reset 0x90 — I/O configuration register for pin PIO1_2/DSR/MISO0/ CT16B1_MAT2/ CT16B1_MAT1
  [10] OD — Open-drain mode.
    values as RESET_PIO0_0.OD
  [9] SLEW — Driver slew rate
    values as RESET_PIO0_0.SLEW
  [6] INV — Invert input
    values as RESET_PIO0_0.INV
  [5] HYS — Hysteresis.
    0=DISABLE_; 1=ENABLE_
  [4:3] MODE — Selects function mode (on-chip pull-up/pull-down resistor control).
    values as RESET_PIO0_0.MODE
  [2:0] FUNC — Selects pin function for pin PIO1_2/DSR/MISO0/ CT16B1_MAT2/ CT16B1_MAT1
    0=PIO1_2 (General purpose digital input/output pin.); 1=DSR (Data Set Ready input for USART.); 2=MISO0 (Master In Slave Out for SSP0.); 3=CT16B1_MAT2 (Match output 2 for 16-bit timer 1.); 4=CT16B1_MAT1 (Match output 1 for 16-bit timer 1.)
0x8C PIO1_3 reset 0x90 — I/O configuration register for pin PIO1_3/RI/MOSI0/ CT16B1_CAP0
  [10] OD — Open-drain mode.
    values as RESET_PIO0_0.OD
  [9] SLEW — Driver slew rate
    values as RESET_PIO0_0.SLEW
  [6] INV — Invert input
    values as RESET_PIO0_0.INV
  [5] HYS — Hysteresis.
    0=DISABLE_; 1=ENABLE_
  [4:3] MODE — Selects function mode (on-chip pull-up/pull-down resistor control).
    values as RESET_PIO0_0.MODE
  [2:0] FUNC — Selects pin function for pin PIO1_3/RI/MOSI0/ CT16B1_CAP0
    0=PIO1_3 (General purpose digital input/output pin.); 1=RI (Ring Indicator input for USART.); 2=MOSI0 (Master Out Slave In for SSP0.); 3=CT16B1_CAP0 (Capture input 0 for 16-bit timer 1.)
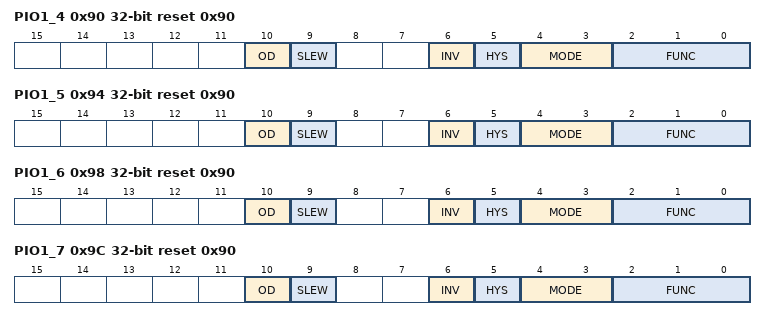
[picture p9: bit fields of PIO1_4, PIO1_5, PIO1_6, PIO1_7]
0x90 PIO1_4 reset 0x90 — I/O configuration register for pin PIO1_4/RXD/SSEL1/ CT32B0_MAT1/ CT32B1_CAP0/ CT16B0_CAP1
  [10] OD — Open-drain mode.
    values as RESET_PIO0_0.OD
  [9] SLEW — Driver slew rate
    values as RESET_PIO0_0.SLEW
  [6] INV — Invert input
    values as RESET_PIO0_0.INV
  [5] HYS — Hysteresis.
    0=DISABLE_; 1=ENABLE_
  [4:3] MODE — Selects function mode (on-chip pull-up/pull-down resistor control).
    values as RESET_PIO0_0.MODE
  [2:0] FUNC — Selects pin function for pin PIO1_4/RXD/SSEL1/ CT32B0_MAT1/ CT32B1_CAP0/ CT16B0_CAP1
    0=PIO1_4 (General purpose digital input/output pin.); 1=RXD (Receiver data input for USART.); 2=SSEL1 (Slave Select for SSP1.); 3=CT32B0_MAT1 (Match output 1 for 32-bit timer 0.); 4=CT32B1_CAP0 (Capture input 0 for 32-bit timer 1.); 5=CT16B0_CAP1 (Capture input 1 for 16-bit timer 0.)
0x94 PIO1_5 reset 0x90 — I/O configuration register for pin PIO1_5/TXD/SCK1/ CT32B0_MAT2/ CT32B1_CAP1/ CT16B0_CAP2
  [10] OD — Open-drain mode.
    values as RESET_PIO0_0.OD
  [9] SLEW — Driver slew rate
    values as RESET_PIO0_0.SLEW
  [6] INV — Invert input
    values as RESET_PIO0_0.INV
  [5] HYS — Hysteresis.
    0=DISABLE_; 1=ENABLE_
  [4:3] MODE — Selects function mode (on-chip pull-up/pull-down resistor control).
    values as RESET_PIO0_0.MODE
  [2:0] FUNC — Selects pin function for pin PIO1_5/TXD/SCK1/ CT32B0_MAT2/ CT32B1_CAP1/ CT16B0_CAP2
    0=PIO1_5 (General purpose digital input/output pin.); 1=TXD (Transmitter data output for USART.); 2=SCK1 (Serial clock for SSP1.); 3=CT32B0_MAT2 (Match output 2 for 32-bit timer 0.); 4=CT32B1_CAP1 (Capture input 1 for 32-bit timer 1.); 5=CT16B0_CAP2 (Capture input 2 for 16-bit timer 0.)
0x98 PIO1_6 reset 0x90 — I/O configuration register for pin PIO1_6/RTS/MOSI1/ CT32B0_MAT3/ CT32B1_CAP2/ CT16B0_MAT0
  [10] OD — Open-drain mode.
    values as RESET_PIO0_0.OD
  [9] SLEW — Driver slew rate
    values as RESET_PIO0_0.SLEW
  [6] INV — Invert input
    values as RESET_PIO0_0.INV
  [5] HYS — Hysteresis.
    0=DISABLE_; 1=ENABLE_
  [4:3] MODE — Selects function mode (on-chip pull-up/pull-down resistor control).
    values as RESET_PIO0_0.MODE
  [2:0] FUNC — Selects pin function for pin PIO1_6/RTS/MOSI1/ CT32B0_MAT3/ CT32B1_CAP2/ CT16B0_MAT0
    0=PIO1_6 (General purpose digital input/output pin.); 1=RTS (Request To Send output for USART.); 2=MOSI1 (Master Out Slave In for SSP1.); 3=CT32B0_MAT3 (Match output 3 for 32-bit timer 0.); 4=CT32B1_CAP2 (Capture input 2 for 32-bit timer 1.); 5=CT16B0_MAT0 (Match output 0 for 16-bit timer 0.)
0x9C PIO1_7 reset 0x90 — I/O configuration register for pin PIO1_7/CTS/MOSI0/ CT32B1_MAT1/ CT16B0_MAT2/ CT16B1_CAP2
  [10] OD — Open-drain mode.
    values as RESET_PIO0_0.OD
  [9] SLEW — Driver slew rate
    values as RESET_PIO0_0.SLEW
  [6] INV — Invert input
    values as RESET_PIO0_0.INV
  [5] HYS — Hysteresis.
    0=DISABLE_; 1=ENABLE_
  [4:3] MODE — Selects function mode (on-chip pull-up/pull-down resistor control).
    values as RESET_PIO0_0.MODE
  [2:0] FUNC — Selects pin function for pin PIO1_7/CTS/MOSI0/ CT32B1_MAT1/ CT16B0_MAT2/ CT16B1_CAP2
    0=PIO1_7 (General purpose digital input/output pin.); 1=CTS (Clear To Send input for USART.); 2=MOSI0 (Master Out Slave In for SSP0.); 3=CT32B1_MAT1 (Match output 1 for 32-bit timer 1.); 4=CT16B0_MAT2 (Match output 2 for 16-bit timer 0.); 5=CT16B1_CAP2 (Capture input 2 for 16-bit timer 1.)
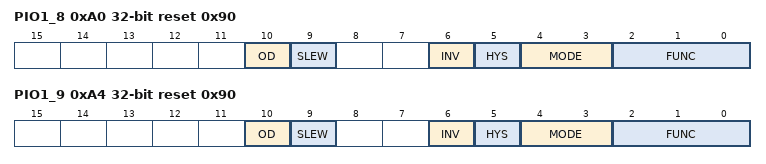
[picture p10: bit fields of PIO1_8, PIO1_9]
0xA0 PIO1_8 reset 0x90 — I/O configuration register for pin PIO1_8/RXD / MISO1/ CT32B1_MAT0/ CT16B1_MAT1
  [10] OD — Open-drain mode.
    values as RESET_PIO0_0.OD
  [9] SLEW — Driver slew rate
    values as RESET_PIO0_0.SLEW
  [6] INV — Invert input
    values as RESET_PIO0_0.INV
  [5] HYS — Hysteresis.
    0=DISABLE_; 1=ENABLE_
  [4:3] MODE — Selects function mode (on-chip pull-up/pull-down resistor control).
    values as RESET_PIO0_0.MODE
  [2:0] FUNC — Selects pin function for pin PIO1_8/RXD / MISO1/ CT32B1_MAT0/ CT16B1_MAT1
    0=PIO1_8 (General purpose digital input/output pin.); 1=RXD (Receiver data input for USART.); 2=MISO1 (Master In Slave Out for SSP1.); 3=CT32B1_MAT0 (Match output 0 for 32-bit timer 1.); 4=CT16B1_MAT1 (Match output 1 for 16-bit timer 1.)
0xA4 PIO1_9 reset 0x90 — I/O configuration register for pin PIO1_9/DCD/R/ CT32B1_MAT2 / CT16B1_MAT2
  [10] OD — Open-drain mode.
    values as RESET_PIO0_0.OD
  [9] SLEW — Driver slew rate
    values as RESET_PIO0_0.SLEW
  [6] INV — Invert input
    values as RESET_PIO0_0.INV
  [5] HYS — Hysteresis.
    0=DISABLE_; 1=ENABLE_
  [4:3] MODE — Selects function mode (on-chip pull-up/pull-down resistor control).
    values as RESET_PIO0_0.MODE
  [2:0] FUNC — Selects pin function for pin PIO1_9/DCD/R/ CT32B1_MAT2 / CT16B1_MAT2
    0=PIO1_9 (General purpose digital input/output pin.); 1=DCD (Data Carrier Detect input for USART.); 2=R (Reserved.); 3=CT32B1_MAT2 (Match output 2 for 32-bit timer 1.); 4=CT16B1_MAT2 (Match output 2 for 16-bit timer 1.)
